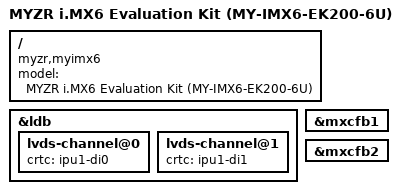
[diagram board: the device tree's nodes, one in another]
/*
 * MYZR Technology Co.,Ltd
 * http://www.myzr.com.cn
 * Tang Bin <tangb@myzr.com.cn>
 */

/dts-v1/;
#include "imx6dl.dtsi"
#include "myimx6ek200-6qu.dtsi"

/ {
	model = "MYZR i.MX6 Evaluation Kit (MY-IMX6-EK200-6U)";
	compatible = "myzr,myimx6", "myzr,myimx6ek200", "myzr,myimx6ek200-6u", "fsl,imx6dl";
};

&ldb {
	lvds-channel@0 {
		crtc = "ipu1-di0";
	};

	lvds-channel@1 {
		crtc = "ipu1-di1";
	};
};

&mxcfb1 {
	status = "okay";
};

&mxcfb2 {
	status = "okay";
};
